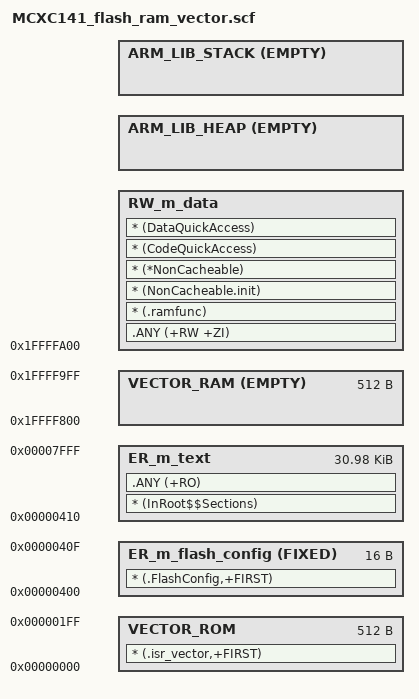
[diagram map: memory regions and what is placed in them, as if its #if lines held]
#!armclang --target=arm-arm-none-eabi -mcpu=cortex-m0plus -E -x c
/*
** ###################################################################
**     Processors:          MCXC141VFM
**                          MCXC141VLH
**
**     Compiler:            Keil ARM C/C++ Compiler
**     Reference manual:    MCXC242RM, Rev.1, Mar 2024
**     Version:             rev. 1.5, 2025-11-07
**     Build:               b251107
**
**     Abstract:
**         Linker file for the Keil ARM C/C++ Compiler
**
**     Copyright 2016 Freescale Semiconductor, Inc.
**     Copyright 2016-2025 NXP
**     SPDX-License-Identifier: BSD-3-Clause
**
**     http:                 www.nxp.com
**     mail:                 support@nxp.com
**
** ###################################################################
*/

#if (defined(__ram_vector_table__))
  #define __ram_vector_table_size__    0x00000200
#else
  #define __ram_vector_table_size__    0x00000000
#endif

#define m_interrupts_start             0x00000000
#define m_interrupts_size              0x00000200

#define m_flash_config_start           0x00000400
#define m_flash_config_size            0x00000010

#define m_text_start                   0x00000410
#define m_text_size                    0x00007BF0

#define m_interrupts_ram_start         0x1FFFF800
#define m_interrupts_ram_size          __ram_vector_table_size__

#define m_data_start                   (m_interrupts_ram_start + m_interrupts_ram_size)
#define m_data_size                    (0x00002000 - m_interrupts_ram_size)

/* Sizes */
#if (defined(__stack_size__))
  #define Stack_Size                   __stack_size__
#else
  #define Stack_Size                   0x0100
#endif

#if (defined(__heap_size__))
  #define Heap_Size                    __heap_size__
#else
  #define Heap_Size                    0x0100
#endif

LR_m_text m_interrupts_start m_text_start+m_text_size-m_interrupts_start { ; load region size_region
  VECTOR_ROM m_interrupts_start m_interrupts_size { ; load address = execution address
    * (.isr_vector,+FIRST)
  }
  ER_m_flash_config m_flash_config_start FIXED m_flash_config_size { ; load address = execution address
    * (.FlashConfig,+FIRST)
  }
  ER_m_text m_text_start m_text_size { ; load address = execution address
    * (InRoot$$Sections)
    .ANY (+RO)
  }

#if (defined(__ram_vector_table__))
  VECTOR_RAM m_interrupts_ram_start EMPTY m_interrupts_ram_size {
  }
#else
  VECTOR_RAM m_interrupts_start EMPTY 0 {
  }
#endif
  RW_m_data m_data_start m_data_size-Stack_Size-Heap_Size { ; RW data
    .ANY (+RW +ZI)
    * (.ramfunc)
    * (NonCacheable.init)
    * (*NonCacheable)
    * (CodeQuickAccess)
    * (DataQuickAccess)
  }
  ARM_LIB_HEAP +0 EMPTY Heap_Size {    ; Heap region growing up
  }
  ARM_LIB_STACK m_data_start+m_data_size EMPTY -Stack_Size { ; Stack region growing down
  }
}

